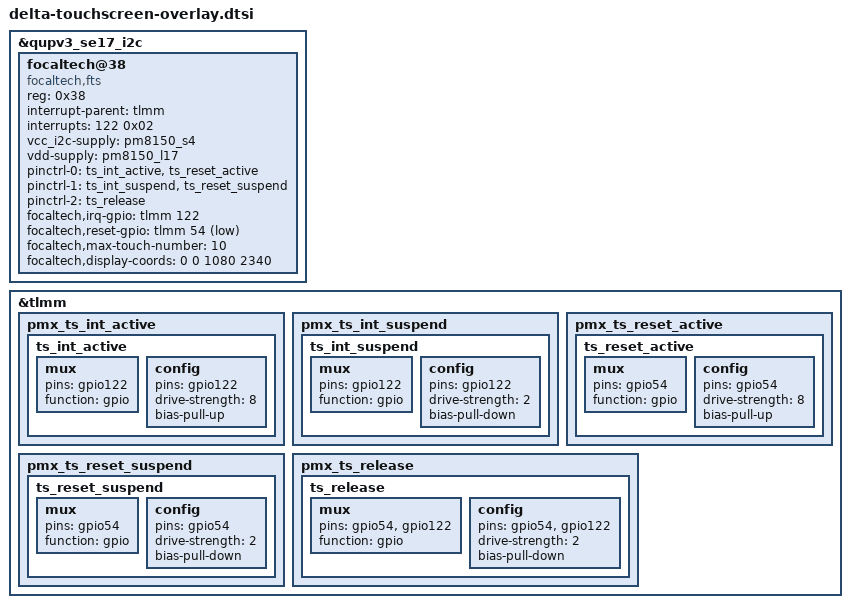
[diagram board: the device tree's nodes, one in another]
/*
 * Copyright (c) 2019, The Linux Foundation. All rights reserved.
 *
 * This program is free software; you can redistribute it and/or modify
 * it under the terms of the GNU General Public License version 2 and
 * only version 2 as published by the Free Software Foundation.
 *
 * This program is distributed in the hope that it will be useful,
 * but WITHOUT ANY WARRANTY; without even the implied warranty of
 * MERCHANTABILITY or FITNESS FOR A PARTICULAR PURPOSE.  See the
 * GNU General Public License for more details.
 */

&qupv3_se17_i2c {
	status = "ok";

	focaltech@38{
		compatible = "focaltech,fts";
		reg = <0x38>;
		interrupt-parent = <&tlmm>;
		interrupts = <122 0x02>;
		vcc_i2c-supply = <&pm8150_s4>;
		vdd-supply = <&pm8150_l17>;
		pinctrl-names = "pmx_ts_active", "pmx_ts_suspend", "pmx_ts_release";
		pinctrl-0 = <&ts_int_active &ts_reset_active>;
		pinctrl-1 = <&ts_int_suspend &ts_reset_suspend>;
		pinctrl-2 = <&ts_release>;
		focaltech,irq-gpio = <&tlmm 122 0x02>;
		focaltech,reset-gpio = <&tlmm 54 0x01>;
		focaltech,max-touch-number = <10>;
		focaltech,display-coords =  <0 0 1080 2340>;
	};
};

&tlmm {
	pmx_ts_int_active {
		ts_int_active: ts_int_active {
			mux {
				pins = "gpio122";
				function = "gpio";
			};

			config {
				pins = "gpio122";
				drive-strength = <8>;
				bias-pull-up;
			};
		};
	};

	pmx_ts_int_suspend {
		ts_int_suspend: ts_int_suspend {
			mux {
				pins = "gpio122";
				function = "gpio";
			};

			config {
				pins = "gpio122";
				drive-strength = <2>;
				bias-pull-down;
			};
		};
	};

	pmx_ts_reset_active {
		ts_reset_active: ts_reset_active {
			mux {
				pins = "gpio54";
				function = "gpio";
			};

			config {
				pins = "gpio54";
				drive-strength = <8>;
				bias-pull-up;
			};
		};
	};

	pmx_ts_reset_suspend {
		ts_reset_suspend: ts_reset_suspend {
			mux {
				pins = "gpio54";
				function = "gpio";
			};

			config {
				pins = "gpio54";
				drive-strength = <2>;
				bias-pull-down;
			};
		};
	};

	pmx_ts_release {
		ts_release: ts_release {
			mux {
				pins = "gpio54", "gpio122";
				function = "gpio";
			};

			config {
				pins = "gpio54", "gpio122";
				drive-strength = <2>;
				bias-pull-down;
			};
		};
	};
};
